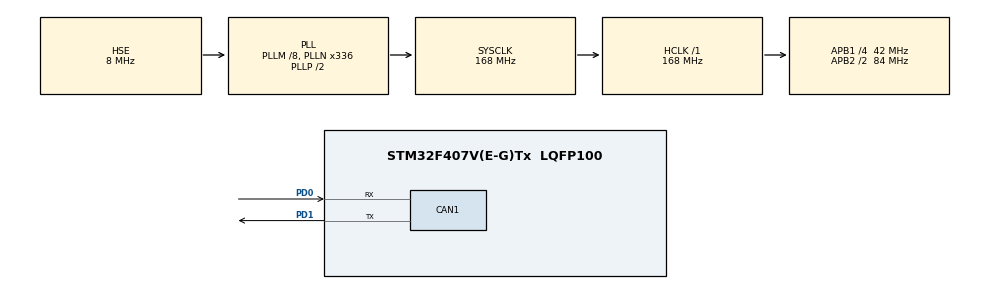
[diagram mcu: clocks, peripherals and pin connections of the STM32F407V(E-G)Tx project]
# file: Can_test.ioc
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CAN1.CalculateTimeQuantum=380.95238095238096
Mcu.Family=STM32F4
Mcu.Name=STM32F407V(E-G)Tx
Mcu.Package=LQFP100
NVIC.CAN1_RX0_IRQn=true\:0\:0\:false\:false\:true\:true\:true
NVIC.CAN1_RX1_IRQn=true\:0\:0\:false\:false\:true\:true\:true
NVIC.CAN1_SCE_IRQn=true\:0\:0\:false\:false\:true\:true\:true
NVIC.PriorityGroup=NVIC_PRIORITYGROUP_0
NVIC.TIM3_IRQn=true\:0\:0\:false\:false\:true\:true\:true
PA13.Mode=Serial_Wire
PA13.Signal=SYS_JTMS-SWDIO
PA14.Mode=Serial_Wire
PA14.Signal=SYS_JTCK-SWCLK
PD0.Mode=Master
PD0.Signal=CAN1_RX
PD1.Mode=Master
PD1.Signal=CAN1_TX
PH0-OSC_IN.Mode=HSE-External-Oscillator
PH0-OSC_IN.Signal=RCC_OSC_IN
PH1-OSC_OUT.Mode=HSE-External-Oscillator
PH1-OSC_OUT.Signal=RCC_OSC_OUT
ProjectManager.HeapSize=0x200
ProjectManager.StackSize=0x400
ProjectManager.TargetToolchain=EWARM V8.32
RCC.48MHZClocksFreq_Value=48000000
RCC.AHBFreq_Value=168000000
RCC.APB1CLKDivider=RCC_HCLK_DIV4
RCC.APB1Freq_Value=42000000
RCC.APB1TimFreq_Value=84000000
RCC.APB2CLKDivider=RCC_HCLK_DIV2
RCC.APB2Freq_Value=84000000
RCC.APB2TimFreq_Value=168000000
RCC.CortexFreq_Value=168000000
RCC.HCLKFreq_Value=168000000
RCC.HSE_VALUE=8000000
RCC.HSI_VALUE=16000000
RCC.LSE_VALUE=32768
RCC.PLLM=8
RCC.PLLN=336
RCC.PLLQ=7
RCC.PLLSourceVirtual=RCC_PLLSOURCE_HSE
RCC.SYSCLKFreq_VALUE=168000000
RCC.SYSCLKSource=RCC_SYSCLKSOURCE_PLLCLK
RCC.VCOOutputFreq_Value=336000000
TIM3.TIM_MasterSlaveMode=TIM_MASTERSLAVEMODE_ENABLE
VP_TIM3_VS_ClockSourceINT.Mode=Internal
board=STM32F407G-DISC1

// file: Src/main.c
/* USER CODE BEGIN Header */
/**
  ******************************************************************************
  * @file           : main.c
  * @brief          : Main program body
  ******************************************************************************
  * @attention
  *
  * <h2><center>&copy; Copyright (c) 2020 STMicroelectronics.
  * All rights reserved.</center></h2>
  *
  * This software component is licensed by ST under BSD 3-Clause license,
  * the "License"; You may not use this file except in compliance with the
  * License. You may obtain a copy of the License at:
  *                        opensource.org/licenses/BSD-3-Clause
  *
  ******************************************************************************
  */
/* USER CODE END Header */

#include "main.h"

CAN_HandleTypeDef hcan1;

TIM_HandleTypeDef htim3;

/* USER CODE BEGIN PV */
CAN_TxHeaderTypeDef TxHeader;
CAN_RxHeaderTypeDef RxHeader;
uint8_t tx_msg[5] = {'h','e','l','l','o'};
uint8_t rcvd_msg[8];
/* USER CODE END PV */

void SystemClock_Config(void);
static void MX_GPIO_Init(void);
static void MX_CAN1_Init(void);
static void MX_TIM3_Init(void);
/* USER CODE BEGIN PFP */
void CAN_TxMsg(void);
/* USER CODE END PFP */

int main(void)
{

  /* MCU Configuration--------------------------------------------------------*/

  /* Reset of all peripherals, Initializes the Flash interface and the Systick. */
  HAL_Init();

  /* Configure the system clock */
  SystemClock_Config();

  /* Initialize all configured peripherals */
  MX_GPIO_Init();
  MX_CAN1_Init();
      HAL_CAN_ActivateNotification(&hcan1, CAN_IT_TX_MAILBOX_EMPTY | CAN_IT_RX_FIFO0_MSG_PENDING |
                                                   CAN_IT_RX_FIFO1_MSG_PENDING | CAN_IT_BUSOFF);

  HAL_CAN_Start(&hcan1);
  MX_TIM3_Init();
  /* USER CODE BEGIN 2 */
  HAL_TIM_Base_Start_IT(&htim3);

  /* USER CODE END 2 */

  /* Infinite loop */
  while (1)
  {

    /* USER CODE BEGIN 3 */
    for(uint32_t i=0; i<65535; i++);
    CAN_TxMsg();
    for(uint32_t i=0; i<65535; i++);
  }
  /* USER CODE END 3 */
}

void SystemClock_Config(void)
{
  RCC_OscInitTypeDef RCC_OscInitStruct = {0};
  RCC_ClkInitTypeDef RCC_ClkInitStruct = {0};

  /** Configure the main internal regulator output voltage
  */
  __HAL_RCC_PWR_CLK_ENABLE();
  __HAL_PWR_VOLTAGESCALING_CONFIG(PWR_REGULATOR_VOLTAGE_SCALE1);
  /** Initializes the CPU, AHB and APB busses clocks
  */
  RCC_OscInitStruct.OscillatorType = RCC_OSCILLATORTYPE_HSE;
  RCC_OscInitStruct.HSEState = RCC_HSE_ON;
  RCC_OscInitStruct.PLL.PLLState = RCC_PLL_ON;
  RCC_OscInitStruct.PLL.PLLSource = RCC_PLLSOURCE_HSE;
  RCC_OscInitStruct.PLL.PLLM = 8;
  RCC_OscInitStruct.PLL.PLLN = 336;
  RCC_OscInitStruct.PLL.PLLP = RCC_PLLP_DIV2;
  RCC_OscInitStruct.PLL.PLLQ = 7;
  if (HAL_RCC_OscConfig(&RCC_OscInitStruct) != HAL_OK)
  {
    Error_Handler();
  }
  /** Initializes the CPU, AHB and APB busses clocks
  */
  RCC_ClkInitStruct.ClockType = RCC_CLOCKTYPE_HCLK|RCC_CLOCKTYPE_SYSCLK
                              |RCC_CLOCKTYPE_PCLK1|RCC_CLOCKTYPE_PCLK2;
  RCC_ClkInitStruct.SYSCLKSource = RCC_SYSCLKSOURCE_PLLCLK;
  RCC_ClkInitStruct.AHBCLKDivider = RCC_SYSCLK_DIV1;
  RCC_ClkInitStruct.APB1CLKDivider = RCC_HCLK_DIV4;
  RCC_ClkInitStruct.APB2CLKDivider = RCC_HCLK_DIV2;

  if (HAL_RCC_ClockConfig(&RCC_ClkInitStruct, FLASH_LATENCY_5) != HAL_OK)
  {
    Error_Handler();
  }
}

static void MX_CAN1_Init(void)
{

  hcan1.Instance = CAN1;
  hcan1.Init.Prescaler = 6;
  hcan1.Init.Mode = CAN_MODE_NORMAL;
  hcan1.Init.SyncJumpWidth = CAN_SJW_1TQ;
  hcan1.Init.TimeSeg1 = CAN_BS1_11TQ;
  hcan1.Init.TimeSeg2 = CAN_BS2_2TQ;
  hcan1.Init.TimeTriggeredMode = DISABLE;
  hcan1.Init.AutoBusOff = DISABLE;
  hcan1.Init.AutoWakeUp = DISABLE;
  hcan1.Init.AutoRetransmission = DISABLE;
  hcan1.Init.ReceiveFifoLocked = DISABLE;
  hcan1.Init.TransmitFifoPriority = DISABLE;
  if (HAL_CAN_Init(&hcan1) != HAL_OK)
  {
    Error_Handler();
  }

}

static void MX_TIM3_Init(void)
{

  /* USER CODE BEGIN TIM3_Init 0 */
__HAL_RCC_TIM3_CLK_ENABLE();
  /* USER CODE END TIM3_Init 0 */

    TIM_ClockConfigTypeDef sClockSourceConfig;
    TIM_MasterConfigTypeDef sMasterConfig;
    htim3.Instance                             = TIM3;
    htim3.Init.Prescaler                       = 20999;
    htim3.Init.CounterMode                     = TIM_COUNTERMODE_UP;
    htim3.Init.Period                          = 1999;
    htim3.Init.ClockDivision                   = TIM_CLOCKDIVISION_DIV1;
    htim3.Init.AutoReloadPreload               = TIM_AUTORELOAD_PRELOAD_DISABLE;
    HAL_TIM_Base_Init(&htim3);

    sClockSourceConfig.ClockSource             = TIM_CLOCKSOURCE_INTERNAL;
    HAL_TIM_ConfigClockSource(&htim3, &sClockSourceConfig);

    sMasterConfig.MasterOutputTrigger          = TIM_TRGO_RESET;
    sMasterConfig.MasterSlaveMode              = TIM_MASTERSLAVEMODE_DISABLE;
    HAL_TIMEx_MasterConfigSynchronization(&htim3, &sMasterConfig);
  /* USER CODE BEGIN TIM3_Init 2 */
        HAL_NVIC_SetPriority(TIM3_IRQn, 0, 0);
        HAL_NVIC_EnableIRQ(TIM3_IRQn);
  /* USER CODE END TIM3_Init 2 */

}

static void MX_GPIO_Init(void)
{

  /* GPIO Ports Clock Enable */
  GPIO_InitTypeDef LED_pin;
  __HAL_RCC_GPIOH_CLK_ENABLE();
  __HAL_RCC_GPIOA_CLK_ENABLE();
  __HAL_RCC_GPIOD_CLK_ENABLE();
     LED_pin.Pin               = GPIO_PIN_12;
     LED_pin.Mode              = GPIO_MODE_OUTPUT_PP;
     LED_pin.Speed             = GPIO_SPEED_FAST;
     LED_pin.Pull              = GPIO_NOPULL;
     HAL_GPIO_Init(GPIOD, &LED_pin);

}

/* USER CODE BEGIN 4 */

/*CAN Transmit message*/
void CAN_TxMsg(void)

{
    uint32_t TxMailbox;

    TxHeader.DLC = 5;
    TxHeader.ExtId = 0x3EA;
    TxHeader.IDE = CAN_ID_EXT;
    TxHeader.RTR = CAN_RTR_DATA;
    HAL_CAN_AddTxMessage(&hcan1,&TxHeader,tx_msg,&TxMailbox);
}

/*CAN Reception fifo0 message pending callback*/

void HAL_CAN_RxFifo0MsgPendingCallback(CAN_HandleTypeDef *hcan)
{
  HAL_CAN_GetRxMessage(&hcan1,CAN_RX_FIFO0,&RxHeader,rcvd_msg);
}

/*timer callback*/
void HAL_TIM_PeriodElapsedCallback (TIM_HandleTypeDef *htim)
{
    if (htim -> Instance == TIM3)
    {
        HAL_GPIO_TogglePin(GPIOD, GPIO_PIN_12);
    }
}
/* USER CODE END 4 */

void Error_Handler(void)
{
}

/************************ (C) COPYRIGHT STMicroelectronics *****END OF FILE****/
